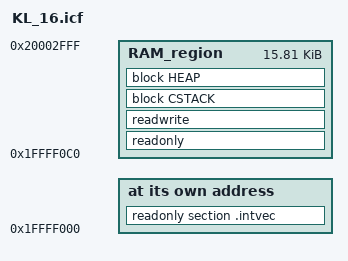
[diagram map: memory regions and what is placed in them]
/* KL_16.icf - for target in SRAM            */
/* 16k RAM                                   */
define symbol __ICFEDIT_intvec_start__ = 0x1ffff000;
/*-Memory Regions-*/
define symbol __ICFEDIT_region_ROM_start__ = 0;
define symbol __ICFEDIT_region_ROM_end__   = 0;
define symbol __ICFEDIT_region_RAM_start__ = 0x1ffff0c0;
define symbol __ICFEDIT_region_RAM_end__   = 0x20002FFF;
/*-Sizes-*/
define symbol __ICFEDIT_size_cstack__ = 0x0;
define symbol __ICFEDIT_size_heap__   = 0x0;
/**** End of ICF editor section. ###ICF###*/


define memory mem with size = 4G;
define region ROM_region   = mem:[from __ICFEDIT_region_ROM_start__   to __ICFEDIT_region_ROM_end__];
define region RAM_region   = mem:[from __ICFEDIT_region_RAM_start__   to __ICFEDIT_region_RAM_end__];

define block CSTACK    with alignment = 8, size = __ICFEDIT_size_cstack__   { };
define block HEAP      with alignment = 8, size = __ICFEDIT_size_heap__     { };

initialize by copy with packing = zeros { readwrite };
do not initialize  { section .noinit };

place at address mem:__ICFEDIT_intvec_start__ { readonly section .intvec };

place in RAM_region   { readonly };
place in RAM_region   { readwrite,
                        block CSTACK, block HEAP };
